# R7FA6M4AF register map
Vendor: Renesas Electronics Corporation; Series: RA6; File version: 1.30.00
CPU: CM33 r0p4, little endian, MPU, FPU, VTOR, 4 interrupt priority bits, 96 interrupts
Registers are 8-bit, read-write, reset 0x0 unless marked. A register's access mark holds for its fields unless they carry their own. Offsets are from the block's base; [hi:lo] are bit positions; {n}, {i} and the like mark numbered series.

## BUS — Bus Control
Base 0x40003000
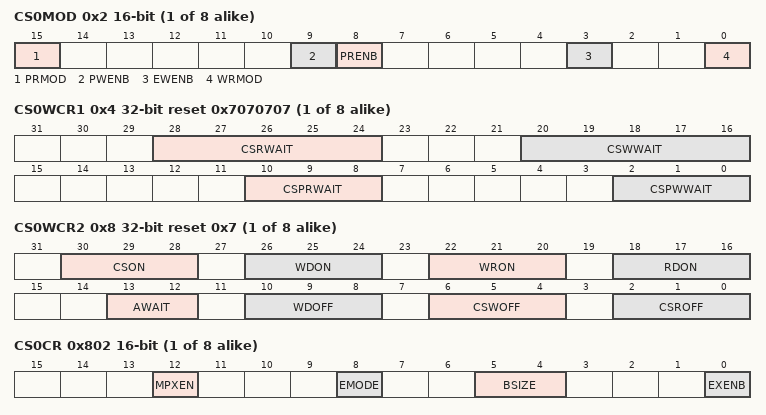
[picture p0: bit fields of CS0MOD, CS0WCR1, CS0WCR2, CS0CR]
{0x2+0x10*i} CS{i}MOD (i=0..7) 16-bit — CS{i} Mode Register
  [15] PRMOD — Page Read Access Mode Select
  [9] PWENB — Page Write Access Enable
  [8] PRENB — Page Read Access Enable
  [3] EWENB — External Wait Enable
  [0] WRMOD — Write Access Mode Select
{0x4+0x10*i} CS{i}WCR1 (i=0..7) 32-bit reset 0x7070707 — CS{i} Wait Control Register 1
  [28:24] CSRWAIT — Normal Read Cycle Wait Select
  [20:16] CSWWAIT — Normal Write Cycle Wait Select
  [10:8] CSPRWAIT — Page Read Cycle Wait Select
  [2:0] CSPWWAIT — Page Write Cycle Wait Select
{0x8+0x10*i} CS{i}WCR2 (i=0..7) 32-bit reset 0x7 — CS{i} Wait Control Register 2
  [30:28] CSON — CS Assert Wait Select
  [26:24] WDON — Write Data Output Wait Select
  [22:20] WRON — WR Assert Wait Select
  [18:16] RDON — RD Assert Wait Select
  [13:12] AWAIT — Address Cycle Wait Select
  [10:8] WDOFF — Write Data Output Extension Cycle Select
  [6:4] CSWOFF — Write,Access CS Extension Cycle Select
  [2:0] CSROFF — Read,Access CS Extension Cycle Select
{0x802+0x10*i} CS{i}CR (i=0..7) 16-bit — CS{i} Control Register
  [12] MPXEN — Address/Data Multiplexed I/O Interface Select
  [8] EMODE — Endian Mode
  [5:4] BSIZE — External Bus Width Select
  [0] EXENB — Operation Enable
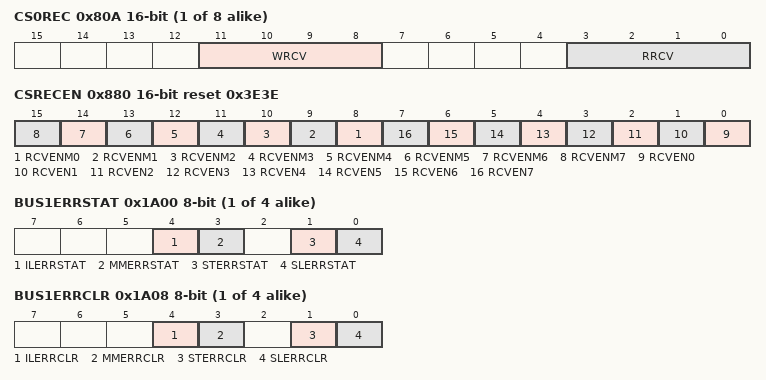
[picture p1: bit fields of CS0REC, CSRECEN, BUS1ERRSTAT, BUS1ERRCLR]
{0x80A+0x10*i} CS{i}REC (i=0..7) 16-bit — CS{i} Recovery Cycle Register
  [11:8] WRCV — Write Recovery
  [3:0] RRCV — Read Recovery
0x880 CSRECEN 16-bit reset 0x3E3E — CS Recovery Cycle Insertion Enable Register
  [n+8] RCVENM{n} (n=0..7) — Multiplexed Bus Recovery Cycle Insertion Enable {n}
  [n] RCVEN{n} (n=0..7) — Separate Bus Recovery Cycle Insertion Enable {n}
0x1100 BUSSCNTFHBIU 16-bit — Slave Bus Control Register
  [1:0] ARBS — Arbitration Select for three masters
0x1104 BUSSCNTFLBIU 16-bit — Slave Bus Control Register
  [1:0] ARBS — Arbitration Select for three masters
0x1110 BUSSCNTS0BIU 16-bit — Slave Bus Control Register
  [1:0] ARBS — Arbitration Select for three masters
0x1120 BUSSCNTPSBIU 16-bit — Slave Bus Control Register
  [0] ARBS — Arbitration Select for two masters
0x1130 BUSSCNTPLBIU 16-bit — Slave Bus Control Register
  [0] ARBS — Arbitration Select for two masters
0x1134 BUSSCNTPHBIU 16-bit — Slave Bus Control Register
  [0] ARBS — Arbitration Select for two masters
0x1140 BUSSCNTEQBIU 16-bit — Slave Bus Control Register
  [1:0] ARBS — Arbitration Select for three masters
0x1144 BUSSCNTEOBIU 16-bit — Slave Bus Control Register
  [1:0] ARBS — Arbitration Select for three masters
0x1148 BUSSCNTECBIU 16-bit — Slave Bus Control Register
  [1:0] ARBS — Arbitration Select for three masters
{0x17F0+0x10*i} BUS{i}ERRADD (i=1..4) 32-bit ro — BUS Error Address Register
  [31:0] BERAD — Bus Error Address
{0x17F4+0x10*i} BUS{i}ERRRW (i=1..4) — BUS Error Read Write Register
  [0] RWSTAT ro — Error Access Read/Write Status
{0x18F0+0x10*i} BTZF{i}ERRADD (i=1..4) 32-bit ro — BUS TZF Error Address Register
  [31:0] BTZFERAD — Bus TrustZone Filter Error Address
{0x18F4+0x10*i} BTZF{i}ERRRW (i=1..4) — BUS TZF Error Read Write Register
  [0] TRWSTAT ro — TrustZone filter error access Read/Write Status
{0x19F0+0x10*i} BUS{i}ERRSTAT (i=1..4) ro — BUS Error Status Register {i}
  [4] ILERRSTAT — Illegal address access Error Status
  [3] MMERRSTAT — Master MPU Error Status
  [1] STERRSTAT — Slave TrustZone filter Error Status
  [0] SLERRSTAT — Slave bus Error Status
{0x19F8+0x10*i} BUS{i}ERRCLR (i=1..4) — BUS Error Clear Register {i}
  [4] ILERRCLR — Illegal Address Access Error Clear
  [3] MMERRCLR — Master MPU Error Clear
  [1] STERRCLR — Slave TrustZone filter Error Clear
  [0] SLERRCLR — Slave bus Error Clear
0x1A24 DMACDTCERRSTAT ro — DMAC/DTC Error Status Register
  [0] MTERRSTAT — Master TrustZone Filter Error Status
0x1A2C DMACDTCERRCLR — DMAC/DTC Error Clear Register
  [0] MTERRCLR — Master TrustZone filter Error Clear
